# M05x_registers register map
File version: 0.1
CPU: 
Registers are 32-bit, read-write, reset 0x0 unless marked. A register's access mark holds for its fields unless they carry their own. Offsets are from the block's base; [hi:lo] are bit positions; lines under a group give offsets from that group; {n}, {i} and the like mark numbered series.

## GP0 — Registers group
Base 0x50004000
Same registers: GP1 0x50004040, GP2 0x50004080, GP3 0x500040C0, GP4 0x50004100
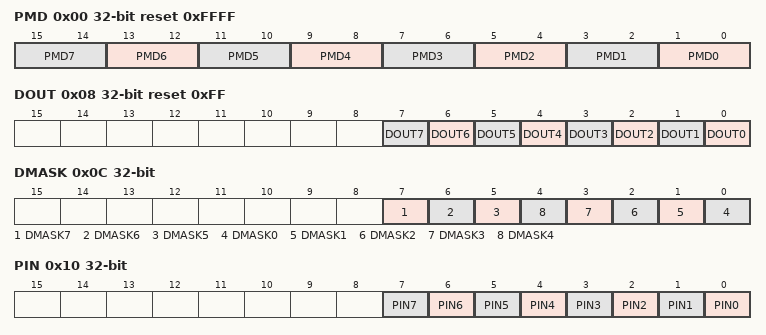
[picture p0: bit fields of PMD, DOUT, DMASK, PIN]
0x00 PMD reset 0xFFFF (reset mask 0xFFFF0000) — Bit Mode Control
  [2n+1:2n] PMD{n} (n=0..7) — P0 I/O Pin[{n}] Mode Control Determine each I/O type of P0 pins 00 = P0[{n}] pin is in INPUT mode. 01 = P0[{n}] pin is in OUTPUT mode. 10 = P0[{n}] pin is in Open-Drain mode. 11 = P0[{n}] pin is in Quasi-bidirectional mode.
0x04 OFFD — Bit OFF Digital Enable
  [23:16] OFFD — OFFD: P0 Pin OFF digital input path Enable 1 = Disable IO digital input path (digital input tied to low) 0 = Enable IO digital input path
0x08 DOUT reset 0xFF (reset mask 0xFFFFFF00) — Data Output Value
  [n] DOUT{n} (n=0..7) — P0 Pin[{n}] Output Value Each of these bits control the status of a P0 pin when the P0 pin is configures as output, open-drain and quasi-mode. 1 = P0 Pin[{n}] will drive High if the corresponding output mode enabling bit is set. 0 = P0 Pin[{n}] will drive Low if the corresponding output mode enabling bit is set.
0x0C DMASK — Data Output Write Mask
  [7] DMASK7 — P0 Data Output Write Mask These bits are used to protect the corresponding register of P0_DOUT bit[7]. When set the DMASK bit[7] to "1", the corresponding DOUT7 bit is protected. The write signal is masked, write data to the protect bit is ignored 0 = The corresponding P0_DOUT[7] bit can be updated 1 = The corresponding P0_DOUT[7] bit is protected
  [6] DMASK6 — P0 Data Output Write Mask These bits are used to protect the corresponding register of P0_DOUT bit[6]. When set the DMASK bit[6] to "1", the corresponding DOUT6 bit is protected. The write signal is masked, write data to the protect bit is ignored 0 = The corresponding P0_DOUT[6] bit can be updated 1 = The corresponding P0_DOUT[6] bit is protected
  [5] DMASK5 — P0 Data Output Write Mask These bits are used to protect the corresponding register of P0_DOUT bit[6]. When set the DMASK bit[6] to "1", the corresponding DOUT6 bit is protected. The write signal is masked, write data to the protect bit is ignored 0 = The corresponding P0_DOUT[6] bit can be updated 1 = The corresponding P0_DOUT[6] bit is protected
  [n] DMASK{n} (n=0..4) — P0 Data Output Write Mask These bits are used to protect the corresponding register of P0_DOUT bit[{n}]. When set the DMASK bit[{n}] to "1", the corresponding DOUT{n} bit is protected. The write signal is masked, write data to the protect bit is ignored 0 = The corresponding P0_DOUT[{n}] bit can be updated 1 = The corresponding P0_DOUT[{n}] bit is protected
0x10 PIN ro (reset mask 0xFFFFFF00) — Pin Value
  [n] PIN{n} (n=0..7) — P0 Pin Values The value read from each of these bit reflects the actual status of the respective P0 Pin[{n}].
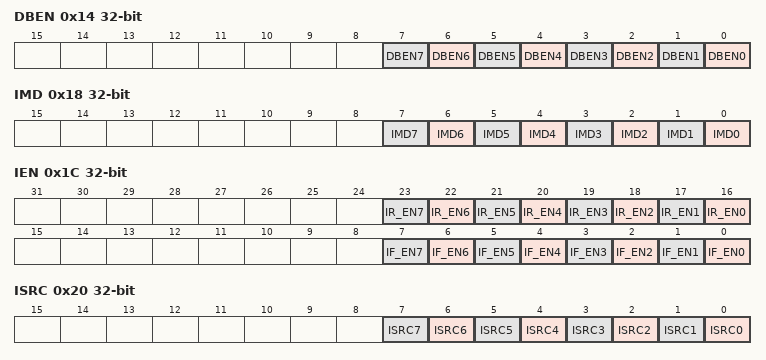
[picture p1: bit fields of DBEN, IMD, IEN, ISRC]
0x14 DBEN — De-bounce Enable
  [n] DBEN{n} (n=0..7) — P0 Input Signal De-bounce Enable DBEN[{n}] used to enable the de-bounce function for each corresponding bit. if the input signal pulse width can't be sampled by continuous two de-bounce sample cycle. The input signal transition is seen as the signal bounce and will not trigger the interrupt. The DBEN[{n}] is used for "edge-trigger" interrupt only, and ignored for "level trigger" interrupt 0 = The bit[{n}] de-bounce function is disabled 1 = The bit[{n}] de-bounce function is enabled The de-bounce function is valid for edge triggered interrupt. if the interrupt mode is level triggered, the de-bounce enable bit is ignored.
0x18 IMD — Interrupt Mode Control
  [n] IMD{n} (n=0..7) — Port 0 Interrupt Mode Control IMD[{n}] used to control the interrupt is by level trigger or by edge trigger. If the interrupt is by edge trigger, the trigger souce is control de-bounce. If the interrupt is by level trigger, the input source is sampled by one clock and the generate the interrupt 0 = Edge trigger interrupt 1 = Level trigger interrupt if set pin as the level trigger interrupt, then only one level can be set on the registers P0_IEN. if set both the level to trigger interrupt, the setting is ignored and no interrupt will occur. The de-bounce function is valid for edge triggered interrupt. if the interrupt mode is level triggered, the de-bounce enable bit is ignored.
0x1C IEN — Interrupt Enable
  [n+16] IR_EN{n} (n=0..7) — Port 0 Interrupt Enable by Input Rising Edge or Input Level High IR_EN[{n}] used to enable the interrupt for each of the corresponding input P0[{n}]. Set bit "1" also enable the pin wakeup function. When set the IR_EN[{n}] bit "1": If the interrupt is level mode trigger, the input P0[{n}] state at level "high" will generate the interrupt. If the interrupt is edge mode trigger, the input P0[{n}] state change from "low-to-high" will generate the interrupt. 1 = Enable the P0[{n}] level-high or low-to-high interrupt 0 = Disable the P0[{n}] level-high or low-to-high interrupt
  [n] IF_EN{n} (n=0..7) — Port0 Interrupt Enable by Input Falling Edge or Input Level Low IF_EN[{n}] used to enable the interrupt for each of the corresponding input P0[{n}]. Set bit "1" also enable the pin wakeup function. When set the IF_EN[{n}] bit "1": If the interrupt is level mode trigger, the input P0[{n}] state at level "low" will generate the interrupt. If the interrupt is edge mode trigger, the input P0[{n}] state change from "high-to-low" will generate the interrupt. 1 = Enable the P0[{n}] state low-level or high-to-low change interrupt 0 = Disable the P0[{n}] state low-level or high-to-low change interrupt
0x20 ISRC reset not defined — Interrupt Trigger Source
  [n] ISRC{n} write-1-clears (n=0..7) — Port 0 Interrupt Trigger Source Indicator Read: 1 = Indicates P0[{n}] generate an interrupt 0 = No interrupt at P0[{n}] Write: 1 = Clear the correspond pending interrupt 0 = No action
